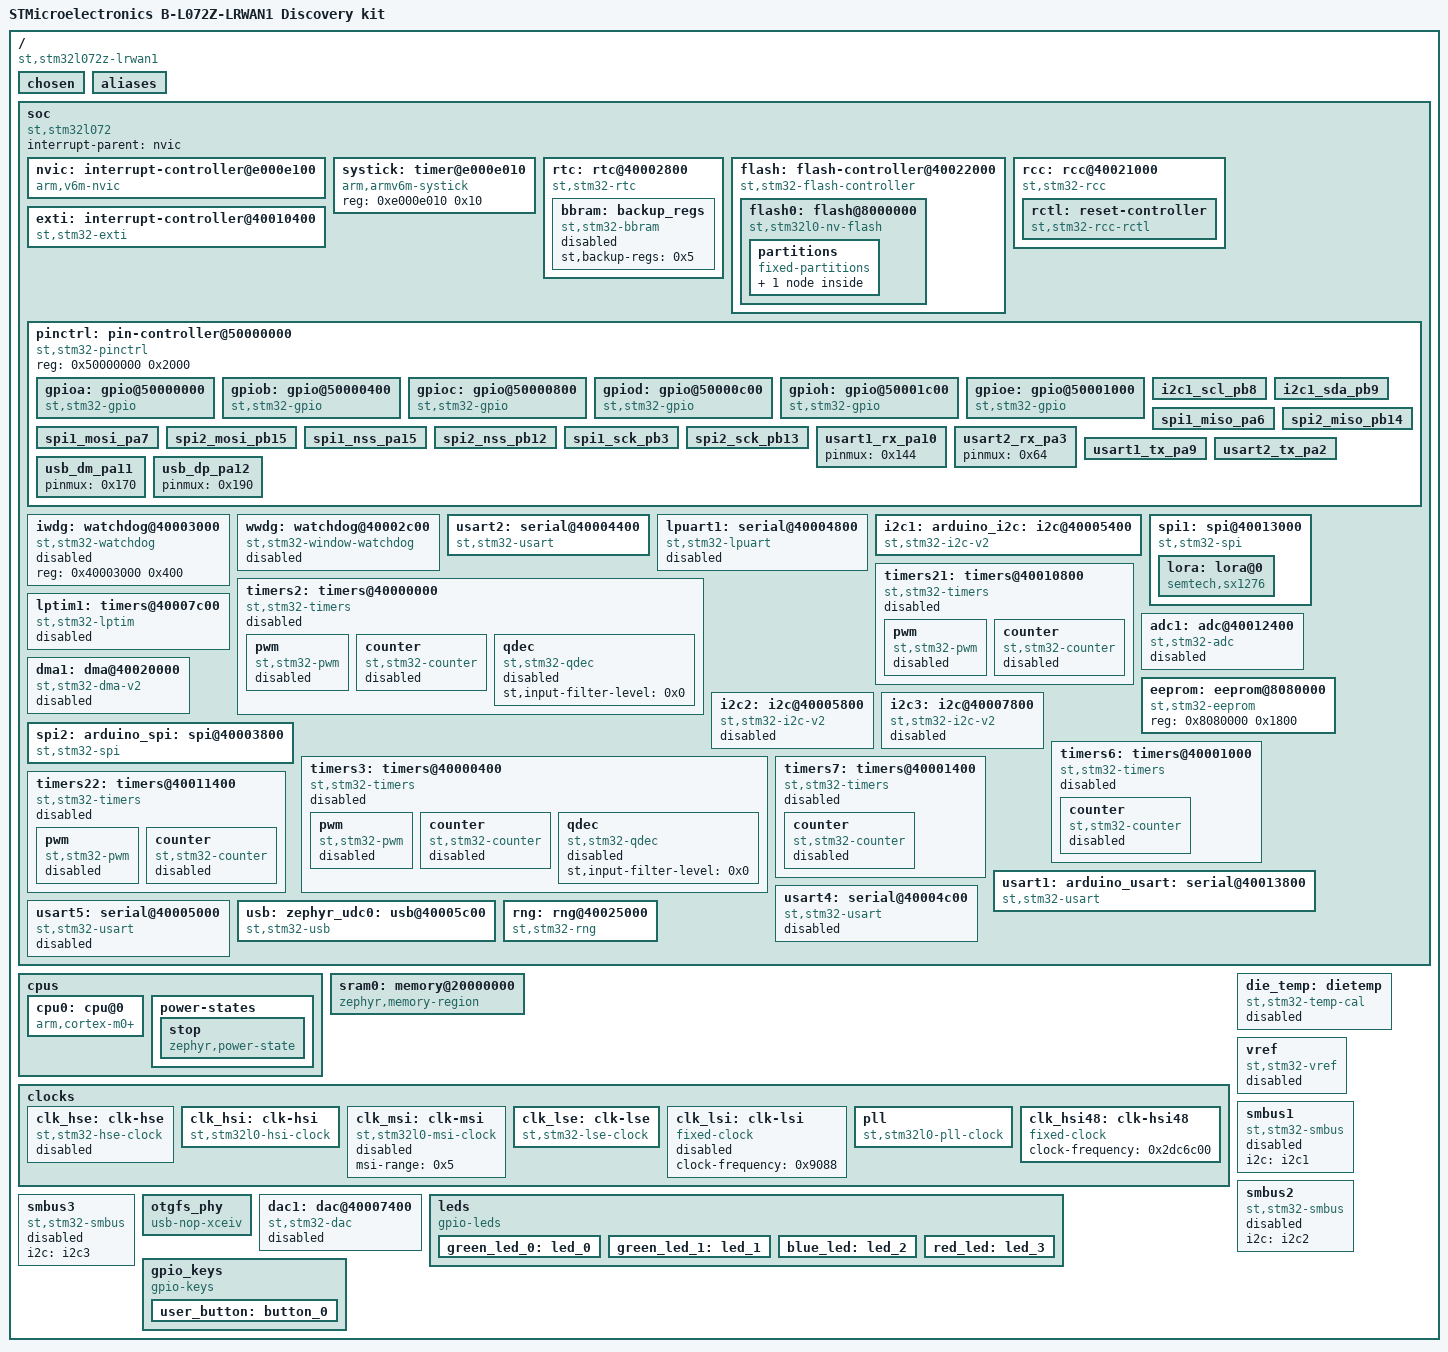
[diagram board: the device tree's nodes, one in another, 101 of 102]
/dts-v1/;

/* node '/' defined in zephyr/dts/common/skeleton.dtsi:9 */
/ {
	#address-cells = < 0x1 >;                                  /* in zephyr/dts/common/skeleton.dtsi:10 */
	#size-cells = < 0x1 >;                                     /* in zephyr/dts/common/skeleton.dtsi:11 */
	model = "STMicroelectronics B-L072Z-LRWAN1 Discovery kit"; /* in zephyr/boards/st/b_l072z_lrwan1/b_l072z_lrwan1.dts:13 */
	compatible = "st,stm32l072z-lrwan1";                       /* in zephyr/boards/st/b_l072z_lrwan1/b_l072z_lrwan1.dts:14 */

	/* node '/chosen' defined in zephyr/dts/common/skeleton.dtsi:13 */
	chosen {
		zephyr,flash-controller = &flash; /* in zephyr/dts/arm/st/l0/stm32l0.dtsi:24 */
		zephyr,entropy = &rng;            /* in zephyr/dts/arm/st/l0/stm32l072.dtsi:11 */
		zephyr,console = &usart2;         /* in zephyr/boards/st/b_l072z_lrwan1/b_l072z_lrwan1.dts:17 */
		zephyr,shell-uart = &usart2;      /* in zephyr/boards/st/b_l072z_lrwan1/b_l072z_lrwan1.dts:18 */
		zephyr,sram = &sram0;             /* in zephyr/boards/st/b_l072z_lrwan1/b_l072z_lrwan1.dts:19 */
		zephyr,flash = &flash0;           /* in zephyr/boards/st/b_l072z_lrwan1/b_l072z_lrwan1.dts:20 */
	};

	/* node '/aliases' defined in zephyr/dts/common/skeleton.dtsi:15 */
	aliases {
		led0 = &green_led_0; /* in zephyr/boards/st/b_l072z_lrwan1/b_l072z_lrwan1.dts:59 */
		led1 = &green_led_1; /* in zephyr/boards/st/b_l072z_lrwan1/b_l072z_lrwan1.dts:60 */
		led2 = &blue_led;    /* in zephyr/boards/st/b_l072z_lrwan1/b_l072z_lrwan1.dts:61 */
		led3 = &red_led;     /* in zephyr/boards/st/b_l072z_lrwan1/b_l072z_lrwan1.dts:62 */
		sw0 = &user_button;  /* in zephyr/boards/st/b_l072z_lrwan1/b_l072z_lrwan1.dts:63 */
		eeprom-0 = &eeprom;  /* in zephyr/boards/st/b_l072z_lrwan1/b_l072z_lrwan1.dts:64 */
		lora0 = &lora;       /* in zephyr/boards/st/b_l072z_lrwan1/b_l072z_lrwan1.dts:65 */
	};

	/* node '/soc' defined in zephyr/dts/arm/armv6-m.dtsi:6 */
	soc {
		#address-cells = < 0x1 >;     /* in zephyr/dts/arm/armv6-m.dtsi:7 */
		#size-cells = < 0x1 >;        /* in zephyr/dts/arm/armv6-m.dtsi:8 */
		interrupt-parent = < &nvic >; /* in zephyr/dts/arm/armv6-m.dtsi:10 */
		ranges;                       /* in zephyr/dts/arm/armv6-m.dtsi:11 */
		compatible = "st,stm32l072",
		             "st,stm32l0",
		             "simple-bus";    /* in zephyr/dts/arm/st/l0/stm32l072.dtsi:24 */

		/* node '/soc/interrupt-controller@e000e100' defined in zephyr/dts/arm/armv6-m.dtsi:13 */
		nvic: interrupt-controller@e000e100 {
			#address-cells = < 0x1 >;            /* in zephyr/dts/arm/armv6-m.dtsi:14 */
			compatible = "arm,v6m-nvic";         /* in zephyr/dts/arm/armv6-m.dtsi:15 */
			reg = < 0xe000e100 0xc00 >;          /* in zephyr/dts/arm/armv6-m.dtsi:16 */
			interrupt-controller;                /* in zephyr/dts/arm/armv6-m.dtsi:17 */
			#interrupt-cells = < 0x2 >;          /* in zephyr/dts/arm/armv6-m.dtsi:18 */
			arm,num-irq-priority-bits = < 0x2 >; /* in zephyr/dts/arm/st/l0/stm32l0.dtsi:384 */
			phandle = < 0x1 >;                   /* in zephyr/dts/arm/armv6-m.dtsi:10 */
		};

		/* node '/soc/timer@e000e010' defined in zephyr/dts/arm/armv6-m.dtsi:21 */
		systick: timer@e000e010 {
			compatible = "arm,armv6m-systick"; /* in zephyr/dts/arm/armv6-m.dtsi:22 */
			reg = < 0xe000e010 0x10 >;         /* in zephyr/dts/arm/armv6-m.dtsi:23 */
		};

		/* node '/soc/rtc@40002800' defined in zephyr/dts/arm/st/l0/stm32l0.dtsi:98 */
		rtc: rtc@40002800 {
			compatible = "st,stm32-rtc";       /* in zephyr/dts/arm/st/l0/stm32l0.dtsi:99 */
			reg = < 0x40002800 0x400 >;        /* in zephyr/dts/arm/st/l0/stm32l0.dtsi:100 */
			interrupts = < 0x2 0x0 >;          /* in zephyr/dts/arm/st/l0/stm32l0.dtsi:101 */
			prescaler = < 0x8000 >;            /* in zephyr/dts/arm/st/l0/stm32l0.dtsi:103 */
			alarms-count = < 0x2 >;            /* in zephyr/dts/arm/st/l0/stm32l0.dtsi:104 */
			alrm-exti-line = < 0x11 >;         /* in zephyr/dts/arm/st/l0/stm32l0.dtsi:105 */
			clocks = < &rcc 0x38 0x10000000 >,
			         < &rcc 0x2 0x1300050 >;   /* in zephyr/boards/st/b_l072z_lrwan1/b_l072z_lrwan1.dts:157 */
			status = "okay";                   /* in zephyr/boards/st/b_l072z_lrwan1/b_l072z_lrwan1.dts:159 */

			/* node '/soc/rtc@40002800/backup_regs' defined in zephyr/dts/arm/st/l0/stm32l0.dtsi:108 */
			bbram: backup_regs {
				compatible = "st,stm32-bbram"; /* in zephyr/dts/arm/st/l0/stm32l0.dtsi:109 */
				st,backup-regs = < 0x5 >;      /* in zephyr/dts/arm/st/l0/stm32l0.dtsi:110 */
				status = "disabled";           /* in zephyr/dts/arm/st/l0/stm32l0.dtsi:111 */
			};
		};

		/* node '/soc/flash-controller@40022000' defined in zephyr/dts/arm/st/l0/stm32l0.dtsi:115 */
		flash: flash-controller@40022000 {
			compatible = "st,stm32-flash-controller",
			             "st,stm32f1-flash-controller"; /* in zephyr/dts/arm/st/l0/stm32l0.dtsi:116 */
			reg = < 0x40022000 0x400 >;                 /* in zephyr/dts/arm/st/l0/stm32l0.dtsi:117 */
			interrupts = < 0x3 0x0 >;                   /* in zephyr/dts/arm/st/l0/stm32l0.dtsi:118 */
			#address-cells = < 0x1 >;                   /* in zephyr/dts/arm/st/l0/stm32l0.dtsi:120 */
			#size-cells = < 0x1 >;                      /* in zephyr/dts/arm/st/l0/stm32l0.dtsi:121 */

			/* node '/soc/flash-controller@40022000/flash@8000000' defined in zephyr/dts/arm/st/l0/stm32l0.dtsi:123 */
			flash0: flash@8000000 {
				compatible = "st,stm32l0-nv-flash",
				             "st,stm32-nv-flash",
				             "soc-nv-flash";        /* in zephyr/dts/arm/st/l0/stm32l0.dtsi:124 */
				write-block-size = < 0x4 >;         /* in zephyr/dts/arm/st/l0/stm32l0.dtsi:127 */
				max-erase-time = < 0x4 >;           /* in zephyr/dts/arm/st/l0/stm32l0.dtsi:129 */
				reg = < 0x8000000 0x30000 >;        /* in zephyr/dts/arm/st/l0/stm32l072Xz.dtsi:17 */

				/* node '/soc/flash-controller@40022000/flash@8000000/partitions' defined in zephyr/boards/st/b_l072z_lrwan1/b_l072z_lrwan1.dts:177 */
				partitions {
					compatible = "fixed-partitions"; /* in zephyr/boards/st/b_l072z_lrwan1/b_l072z_lrwan1.dts:178 */
					#address-cells = < 0x1 >;        /* in zephyr/boards/st/b_l072z_lrwan1/b_l072z_lrwan1.dts:179 */
					#size-cells = < 0x1 >;           /* in zephyr/boards/st/b_l072z_lrwan1/b_l072z_lrwan1.dts:180 */

					/* node '/soc/flash-controller@40022000/flash@8000000/partitions/partition@28000' defined in zephyr/boards/st/b_l072z_lrwan1/b_l072z_lrwan1.dts:183 */
					storage_partition: partition@28000 {
						label = "storage";        /* in zephyr/boards/st/b_l072z_lrwan1/b_l072z_lrwan1.dts:184 */
						reg = < 0x28000 0x8000 >; /* in zephyr/boards/st/b_l072z_lrwan1/b_l072z_lrwan1.dts:185 */
					};
				};
			};
		};

		/* node '/soc/rcc@40021000' defined in zephyr/dts/arm/st/l0/stm32l0.dtsi:133 */
		rcc: rcc@40021000 {
			compatible = "st,stm32-rcc";     /* in zephyr/dts/arm/st/l0/stm32l0.dtsi:134 */
			#clock-cells = < 0x2 >;          /* in zephyr/dts/arm/st/l0/stm32l0.dtsi:135 */
			reg = < 0x40021000 0x400 >;      /* in zephyr/dts/arm/st/l0/stm32l0.dtsi:136 */
			clocks = < &pll >;               /* in zephyr/boards/st/b_l072z_lrwan1/b_l072z_lrwan1.dts:89 */
			clock-frequency = < 0x1e84800 >; /* in zephyr/boards/st/b_l072z_lrwan1/b_l072z_lrwan1.dts:90 */
			ahb-prescaler = < 0x1 >;         /* in zephyr/boards/st/b_l072z_lrwan1/b_l072z_lrwan1.dts:91 */
			apb1-prescaler = < 0x1 >;        /* in zephyr/boards/st/b_l072z_lrwan1/b_l072z_lrwan1.dts:92 */
			apb2-prescaler = < 0x1 >;        /* in zephyr/boards/st/b_l072z_lrwan1/b_l072z_lrwan1.dts:93 */
			phandle = < 0x2 >;               /* in zephyr/boards/st/b_l072z_lrwan1/b_l072z_lrwan1.dts:157 */

			/* node '/soc/rcc@40021000/reset-controller' defined in zephyr/dts/arm/st/l0/stm32l0.dtsi:138 */
			rctl: reset-controller {
				compatible = "st,stm32-rcc-rctl"; /* in zephyr/dts/arm/st/l0/stm32l0.dtsi:139 */
				#reset-cells = < 0x1 >;           /* in zephyr/dts/arm/st/l0/stm32l0.dtsi:140 */
				phandle = < 0x4 >;                /* in zephyr/dts/arm/st/l0/stm32l0.dtsi:222 */
			};
		};

		/* node '/soc/interrupt-controller@40010400' defined in zephyr/dts/arm/st/l0/stm32l0.dtsi:144 */
		exti: interrupt-controller@40010400 {
			compatible = "st,stm32-exti"; /* in zephyr/dts/arm/st/l0/stm32l0.dtsi:145 */
			interrupt-controller;         /* in zephyr/dts/arm/st/l0/stm32l0.dtsi:146 */
			#interrupt-cells = < 0x1 >;   /* in zephyr/dts/arm/st/l0/stm32l0.dtsi:147 */
			#address-cells = < 0x0 >;     /* in zephyr/dts/arm/st/l0/stm32l0.dtsi:148 */
			reg = < 0x40010400 0x400 >;   /* in zephyr/dts/arm/st/l0/stm32l0.dtsi:149 */
			clocks = < &rcc 0x34 0x1 >;   /* in zephyr/dts/arm/st/l0/stm32l0.dtsi:150 */
			num-lines = < 0x20 >;         /* in zephyr/dts/arm/st/l0/stm32l0.dtsi:151 */
			interrupts = < 0x5 0x0 >,
			             < 0x6 0x0 >,
			             < 0x7 0x0 >;     /* in zephyr/dts/arm/st/l0/stm32l0.dtsi:152 */
			interrupt-names = "line0-1",
			                  "line2-3",
			                  "line4-15"; /* in zephyr/dts/arm/st/l0/stm32l0.dtsi:153 */
			line-ranges = < 0x0 0x2 >,
			              < 0x2 0x2 >,
			              < 0x4 0xc >;    /* in zephyr/dts/arm/st/l0/stm32l0.dtsi:154 */
		};

		/* node '/soc/pin-controller@50000000' defined in zephyr/dts/arm/st/l0/stm32l0.dtsi:157 */
		pinctrl: pin-controller@50000000 {
			compatible = "st,stm32-pinctrl"; /* in zephyr/dts/arm/st/l0/stm32l0.dtsi:158 */
			#address-cells = < 0x1 >;        /* in zephyr/dts/arm/st/l0/stm32l0.dtsi:159 */
			#size-cells = < 0x1 >;           /* in zephyr/dts/arm/st/l0/stm32l0.dtsi:160 */
			reg = < 0x50000000 0x2000 >;     /* in zephyr/dts/arm/st/l0/stm32l0.dtsi:161 */

			/* node '/soc/pin-controller@50000000/gpio@50000000' defined in zephyr/dts/arm/st/l0/stm32l0.dtsi:163 */
			gpioa: gpio@50000000 {
				compatible = "st,stm32-gpio"; /* in zephyr/dts/arm/st/l0/stm32l0.dtsi:164 */
				gpio-controller;              /* in zephyr/dts/arm/st/l0/stm32l0.dtsi:165 */
				#gpio-cells = < 0x2 >;        /* in zephyr/dts/arm/st/l0/stm32l0.dtsi:166 */
				reg = < 0x50000000 0x400 >;   /* in zephyr/dts/arm/st/l0/stm32l0.dtsi:167 */
				clocks = < &rcc 0x2c 0x1 >;   /* in zephyr/dts/arm/st/l0/stm32l0.dtsi:168 */
				phandle = < 0xd >;            /* in zephyr/boards/st/b_l072z_lrwan1/b_l072z_lrwan1.dts:121 */
			};

			/* node '/soc/pin-controller@50000000/gpio@50000400' defined in zephyr/dts/arm/st/l0/stm32l0.dtsi:171 */
			gpiob: gpio@50000400 {
				compatible = "st,stm32-gpio"; /* in zephyr/dts/arm/st/l0/stm32l0.dtsi:172 */
				gpio-controller;              /* in zephyr/dts/arm/st/l0/stm32l0.dtsi:173 */
				#gpio-cells = < 0x2 >;        /* in zephyr/dts/arm/st/l0/stm32l0.dtsi:174 */
				reg = < 0x50000400 0x400 >;   /* in zephyr/dts/arm/st/l0/stm32l0.dtsi:175 */
				clocks = < &rcc 0x2c 0x2 >;   /* in zephyr/dts/arm/st/l0/stm32l0.dtsi:176 */
				phandle = < 0xf >;            /* in zephyr/boards/st/b_l072z_lrwan1/b_l072z_lrwan1.dts:127 */
			};

			/* node '/soc/pin-controller@50000000/gpio@50000800' defined in zephyr/dts/arm/st/l0/stm32l0.dtsi:179 */
			gpioc: gpio@50000800 {
				compatible = "st,stm32-gpio"; /* in zephyr/dts/arm/st/l0/stm32l0.dtsi:180 */
				gpio-controller;              /* in zephyr/dts/arm/st/l0/stm32l0.dtsi:181 */
				#gpio-cells = < 0x2 >;        /* in zephyr/dts/arm/st/l0/stm32l0.dtsi:182 */
				reg = < 0x50000800 0x400 >;   /* in zephyr/dts/arm/st/l0/stm32l0.dtsi:183 */
				clocks = < &rcc 0x2c 0x4 >;   /* in zephyr/dts/arm/st/l0/stm32l0.dtsi:184 */
				phandle = < 0xe >;            /* in zephyr/boards/st/b_l072z_lrwan1/b_l072z_lrwan1.dts:126 */
			};

			/* node '/soc/pin-controller@50000000/gpio@50000c00' defined in zephyr/dts/arm/st/l0/stm32l0.dtsi:187 */
			gpiod: gpio@50000c00 {
				compatible = "st,stm32-gpio"; /* in zephyr/dts/arm/st/l0/stm32l0.dtsi:188 */
				gpio-controller;              /* in zephyr/dts/arm/st/l0/stm32l0.dtsi:189 */
				#gpio-cells = < 0x2 >;        /* in zephyr/dts/arm/st/l0/stm32l0.dtsi:190 */
				reg = < 0x50000c00 0x400 >;   /* in zephyr/dts/arm/st/l0/stm32l0.dtsi:191 */
				clocks = < &rcc 0x2c 0x8 >;   /* in zephyr/dts/arm/st/l0/stm32l0.dtsi:192 */
			};

			/* node '/soc/pin-controller@50000000/gpio@50001c00' defined in zephyr/dts/arm/st/l0/stm32l0.dtsi:195 */
			gpioh: gpio@50001c00 {
				compatible = "st,stm32-gpio"; /* in zephyr/dts/arm/st/l0/stm32l0.dtsi:196 */
				gpio-controller;              /* in zephyr/dts/arm/st/l0/stm32l0.dtsi:197 */
				#gpio-cells = < 0x2 >;        /* in zephyr/dts/arm/st/l0/stm32l0.dtsi:198 */
				reg = < 0x50001c00 0x400 >;   /* in zephyr/dts/arm/st/l0/stm32l0.dtsi:199 */
				clocks = < &rcc 0x2c 0x80 >;  /* in zephyr/dts/arm/st/l0/stm32l0.dtsi:200 */
			};

			/* node '/soc/pin-controller@50000000/gpio@50001000' defined in zephyr/dts/arm/st/l0/stm32l071.dtsi:14 */
			gpioe: gpio@50001000 {
				compatible = "st,stm32-gpio"; /* in zephyr/dts/arm/st/l0/stm32l071.dtsi:15 */
				gpio-controller;              /* in zephyr/dts/arm/st/l0/stm32l071.dtsi:16 */
				#gpio-cells = < 0x2 >;        /* in zephyr/dts/arm/st/l0/stm32l071.dtsi:17 */
				reg = < 0x50001000 0x400 >;   /* in zephyr/dts/arm/st/l0/stm32l071.dtsi:18 */
				clocks = < &rcc 0x2c 0x10 >;  /* in zephyr/dts/arm/st/l0/stm32l071.dtsi:19 */
			};

			/* node '/soc/pin-controller@50000000/i2c1_scl_pb8' defined in modules/hal/stm32/dts/st/l0/stm32l072c(b-z)tx-pinctrl.dtsi:309 */
			i2c1_scl_pb8: i2c1_scl_pb8 {
				pinmux = < 0x304 >; /* in modules/hal/stm32/dts/st/l0/stm32l072c(b-z)tx-pinctrl.dtsi:310 */
				bias-pull-up;       /* in modules/hal/stm32/dts/st/l0/stm32l072c(b-z)tx-pinctrl.dtsi:311 */
				drive-open-drain;   /* in modules/hal/stm32/dts/st/l0/stm32l072c(b-z)tx-pinctrl.dtsi:312 */
				phandle = < 0x7 >;  /* in zephyr/boards/st/b_l072z_lrwan1/b_l072z_lrwan1.dts:150 */
			};

			/* node '/soc/pin-controller@50000000/i2c1_sda_pb9' defined in modules/hal/stm32/dts/st/l0/stm32l072c(b-z)tx-pinctrl.dtsi:347 */
			i2c1_sda_pb9: i2c1_sda_pb9 {
				pinmux = < 0x324 >; /* in modules/hal/stm32/dts/st/l0/stm32l072c(b-z)tx-pinctrl.dtsi:348 */
				bias-pull-up;       /* in modules/hal/stm32/dts/st/l0/stm32l072c(b-z)tx-pinctrl.dtsi:349 */
				drive-open-drain;   /* in modules/hal/stm32/dts/st/l0/stm32l072c(b-z)tx-pinctrl.dtsi:350 */
				phandle = < 0x8 >;  /* in zephyr/boards/st/b_l072z_lrwan1/b_l072z_lrwan1.dts:150 */
			};

			/* node '/soc/pin-controller@50000000/spi1_miso_pa6' defined in modules/hal/stm32/dts/st/l0/stm32l072c(b-z)tx-pinctrl.dtsi:447 */
			spi1_miso_pa6: spi1_miso_pa6 {
				pinmux = < 0xc0 >; /* in modules/hal/stm32/dts/st/l0/stm32l072c(b-z)tx-pinctrl.dtsi:448 */
				bias-pull-down;    /* in modules/hal/stm32/dts/st/l0/stm32l072c(b-z)tx-pinctrl.dtsi:449 */
				phandle = < 0xb >; /* in zephyr/boards/st/b_l072z_lrwan1/b_l072z_lrwan1.dts:117 */
			};

			/* node '/soc/pin-controller@50000000/spi2_miso_pb14' defined in modules/hal/stm32/dts/st/l0/stm32l072c(b-z)tx-pinctrl.dtsi:462 */
			spi2_miso_pb14: spi2_miso_pb14 {
				pinmux = < 0x3c0 >; /* in modules/hal/stm32/dts/st/l0/stm32l072c(b-z)tx-pinctrl.dtsi:463 */
				bias-pull-down;     /* in modules/hal/stm32/dts/st/l0/stm32l072c(b-z)tx-pinctrl.dtsi:464 */
				phandle = < 0x12 >; /* in zephyr/boards/st/b_l072z_lrwan1/b_l072z_lrwan1.dts:143 */
			};

			/* node '/soc/pin-controller@50000000/spi1_mosi_pa7' defined in modules/hal/stm32/dts/st/l0/stm32l072c(b-z)tx-pinctrl.dtsi:469 */
			spi1_mosi_pa7: spi1_mosi_pa7 {
				pinmux = < 0xe0 >; /* in modules/hal/stm32/dts/st/l0/stm32l072c(b-z)tx-pinctrl.dtsi:470 */
				bias-pull-down;    /* in modules/hal/stm32/dts/st/l0/stm32l072c(b-z)tx-pinctrl.dtsi:471 */
				phandle = < 0xc >; /* in zephyr/boards/st/b_l072z_lrwan1/b_l072z_lrwan1.dts:117 */
			};

			/* node '/soc/pin-controller@50000000/spi2_mosi_pb15' defined in modules/hal/stm32/dts/st/l0/stm32l072c(b-z)tx-pinctrl.dtsi:484 */
			spi2_mosi_pb15: spi2_mosi_pb15 {
				pinmux = < 0x3e0 >; /* in modules/hal/stm32/dts/st/l0/stm32l072c(b-z)tx-pinctrl.dtsi:485 */
				bias-pull-down;     /* in modules/hal/stm32/dts/st/l0/stm32l072c(b-z)tx-pinctrl.dtsi:486 */
				phandle = < 0x13 >; /* in zephyr/boards/st/b_l072z_lrwan1/b_l072z_lrwan1.dts:143 */
			};

			/* node '/soc/pin-controller@50000000/spi1_nss_pa15' defined in modules/hal/stm32/dts/st/l0/stm32l072c(b-z)tx-pinctrl.dtsi:496 */
			spi1_nss_pa15: spi1_nss_pa15 {
				pinmux = < 0x1e0 >; /* in modules/hal/stm32/dts/st/l0/stm32l072c(b-z)tx-pinctrl.dtsi:497 */
				bias-pull-up;       /* in modules/hal/stm32/dts/st/l0/stm32l072c(b-z)tx-pinctrl.dtsi:498 */
				phandle = < 0x9 >;  /* in zephyr/boards/st/b_l072z_lrwan1/b_l072z_lrwan1.dts:117 */
			};

			/* node '/soc/pin-controller@50000000/spi2_nss_pb12' defined in modules/hal/stm32/dts/st/l0/stm32l072c(b-z)tx-pinctrl.dtsi:506 */
			spi2_nss_pb12: spi2_nss_pb12 {
				pinmux = < 0x380 >; /* in modules/hal/stm32/dts/st/l0/stm32l072c(b-z)tx-pinctrl.dtsi:507 */
				bias-pull-up;       /* in modules/hal/stm32/dts/st/l0/stm32l072c(b-z)tx-pinctrl.dtsi:508 */
				phandle = < 0x10 >; /* in zephyr/boards/st/b_l072z_lrwan1/b_l072z_lrwan1.dts:143 */
			};

			/* node '/soc/pin-controller@50000000/spi1_sck_pb3' defined in modules/hal/stm32/dts/st/l0/stm32l072c(b-z)tx-pinctrl.dtsi:519 */
			spi1_sck_pb3: spi1_sck_pb3 {
				pinmux = < 0x260 >;            /* in modules/hal/stm32/dts/st/l0/stm32l072c(b-z)tx-pinctrl.dtsi:520 */
				bias-pull-down;                /* in modules/hal/stm32/dts/st/l0/stm32l072c(b-z)tx-pinctrl.dtsi:521 */
				slew-rate = "very-high-speed"; /* in modules/hal/stm32/dts/st/l0/stm32l072c(b-z)tx-pinctrl.dtsi:522 */
				phandle = < 0xa >;             /* in zephyr/boards/st/b_l072z_lrwan1/b_l072z_lrwan1.dts:117 */
			};

			/* node '/soc/pin-controller@50000000/spi2_sck_pb13' defined in modules/hal/stm32/dts/st/l0/stm32l072c(b-z)tx-pinctrl.dtsi:531 */
			spi2_sck_pb13: spi2_sck_pb13 {
				pinmux = < 0x3a0 >;            /* in modules/hal/stm32/dts/st/l0/stm32l072c(b-z)tx-pinctrl.dtsi:532 */
				bias-pull-down;                /* in modules/hal/stm32/dts/st/l0/stm32l072c(b-z)tx-pinctrl.dtsi:533 */
				slew-rate = "very-high-speed"; /* in modules/hal/stm32/dts/st/l0/stm32l072c(b-z)tx-pinctrl.dtsi:534 */
				phandle = < 0x11 >;            /* in zephyr/boards/st/b_l072z_lrwan1/b_l072z_lrwan1.dts:143 */
			};

			/* node '/soc/pin-controller@50000000/usart1_rx_pa10' defined in modules/hal/stm32/dts/st/l0/stm32l072c(b-z)tx-pinctrl.dtsi:855 */
			usart1_rx_pa10: usart1_rx_pa10 {
				pinmux = < 0x144 >; /* in modules/hal/stm32/dts/st/l0/stm32l072c(b-z)tx-pinctrl.dtsi:856 */
				phandle = < 0x15 >; /* in zephyr/boards/st/b_l072z_lrwan1/b_l072z_lrwan1.dts:103 */
			};

			/* node '/soc/pin-controller@50000000/usart2_rx_pa3' defined in modules/hal/stm32/dts/st/l0/stm32l072c(b-z)tx-pinctrl.dtsi:875 */
			usart2_rx_pa3: usart2_rx_pa3 {
				pinmux = < 0x64 >; /* in modules/hal/stm32/dts/st/l0/stm32l072c(b-z)tx-pinctrl.dtsi:876 */
				phandle = < 0x6 >; /* in zephyr/boards/st/b_l072z_lrwan1/b_l072z_lrwan1.dts:110 */
			};

			/* node '/soc/pin-controller@50000000/usart1_tx_pa9' defined in modules/hal/stm32/dts/st/l0/stm32l072c(b-z)tx-pinctrl.dtsi:898 */
			usart1_tx_pa9: usart1_tx_pa9 {
				pinmux = < 0x124 >; /* in modules/hal/stm32/dts/st/l0/stm32l072c(b-z)tx-pinctrl.dtsi:899 */
				bias-pull-up;       /* in modules/hal/stm32/dts/st/l0/stm32l072c(b-z)tx-pinctrl.dtsi:900 */
				phandle = < 0x14 >; /* in zephyr/boards/st/b_l072z_lrwan1/b_l072z_lrwan1.dts:103 */
			};

			/* node '/soc/pin-controller@50000000/usart2_tx_pa2' defined in modules/hal/stm32/dts/st/l0/stm32l072c(b-z)tx-pinctrl.dtsi:923 */
			usart2_tx_pa2: usart2_tx_pa2 {
				pinmux = < 0x44 >; /* in modules/hal/stm32/dts/st/l0/stm32l072c(b-z)tx-pinctrl.dtsi:924 */
				bias-pull-up;      /* in modules/hal/stm32/dts/st/l0/stm32l072c(b-z)tx-pinctrl.dtsi:925 */
				phandle = < 0x5 >; /* in zephyr/boards/st/b_l072z_lrwan1/b_l072z_lrwan1.dts:110 */
			};

			/* node '/soc/pin-controller@50000000/usb_dm_pa11' defined in modules/hal/stm32/dts/st/l0/stm32l072c(b-z)tx-pinctrl.dtsi:945 */
			usb_dm_pa11: usb_dm_pa11 {
				pinmux = < 0x170 >; /* in modules/hal/stm32/dts/st/l0/stm32l072c(b-z)tx-pinctrl.dtsi:946 */
				phandle = < 0x17 >; /* in zephyr/boards/st/b_l072z_lrwan1/b_l072z_lrwan1.dts:171 */
			};

			/* node '/soc/pin-controller@50000000/usb_dp_pa12' defined in modules/hal/stm32/dts/st/l0/stm32l072c(b-z)tx-pinctrl.dtsi:949 */
			usb_dp_pa12: usb_dp_pa12 {
				pinmux = < 0x190 >; /* in modules/hal/stm32/dts/st/l0/stm32l072c(b-z)tx-pinctrl.dtsi:950 */
				phandle = < 0x18 >; /* in zephyr/boards/st/b_l072z_lrwan1/b_l072z_lrwan1.dts:171 */
			};
		};

		/* node '/soc/watchdog@40003000' defined in zephyr/dts/arm/st/l0/stm32l0.dtsi:204 */
		iwdg: watchdog@40003000 {
			compatible = "st,stm32-watchdog"; /* in zephyr/dts/arm/st/l0/stm32l0.dtsi:205 */
			reg = < 0x40003000 0x400 >;       /* in zephyr/dts/arm/st/l0/stm32l0.dtsi:206 */
			status = "disabled";              /* in zephyr/dts/arm/st/l0/stm32l0.dtsi:207 */
		};

		/* node '/soc/watchdog@40002c00' defined in zephyr/dts/arm/st/l0/stm32l0.dtsi:210 */
		wwdg: watchdog@40002c00 {
			compatible = "st,stm32-window-watchdog"; /* in zephyr/dts/arm/st/l0/stm32l0.dtsi:211 */
			reg = < 0x40002c00 0x400 >;              /* in zephyr/dts/arm/st/l0/stm32l0.dtsi:212 */
			clocks = < &rcc 0x38 0x800 >;            /* in zephyr/dts/arm/st/l0/stm32l0.dtsi:213 */
			interrupts = < 0x0 0x2 >;                /* in zephyr/dts/arm/st/l0/stm32l0.dtsi:214 */
			status = "disabled";                     /* in zephyr/dts/arm/st/l0/stm32l0.dtsi:215 */
		};

		/* node '/soc/serial@40004400' defined in zephyr/dts/arm/st/l0/stm32l0.dtsi:218 */
		usart2: serial@40004400 {
			compatible = "st,stm32-usart",
			             "st,stm32-uart";                  /* in zephyr/dts/arm/st/l0/stm32l0.dtsi:219 */
			reg = < 0x40004400 0x400 >;                    /* in zephyr/dts/arm/st/l0/stm32l0.dtsi:220 */
			clocks = < &rcc 0x38 0x20000 >;                /* in zephyr/dts/arm/st/l0/stm32l0.dtsi:221 */
			resets = < &rctl 0x511 >;                      /* in zephyr/dts/arm/st/l0/stm32l0.dtsi:222 */
			interrupts = < 0x1c 0x0 >;                     /* in zephyr/dts/arm/st/l0/stm32l0.dtsi:223 */
			pinctrl-0 = < &usart2_tx_pa2 &usart2_rx_pa3 >; /* in zephyr/boards/st/b_l072z_lrwan1/b_l072z_lrwan1.dts:110 */
			pinctrl-names = "default";                     /* in zephyr/boards/st/b_l072z_lrwan1/b_l072z_lrwan1.dts:111 */
			current-speed = < 0x1c200 >;                   /* in zephyr/boards/st/b_l072z_lrwan1/b_l072z_lrwan1.dts:112 */
			status = "okay";                               /* in zephyr/boards/st/b_l072z_lrwan1/b_l072z_lrwan1.dts:113 */
		};

		/* node '/soc/serial@40004800' defined in zephyr/dts/arm/st/l0/stm32l0.dtsi:227 */
		lpuart1: serial@40004800 {
			compatible = "st,stm32-lpuart",
			             "st,stm32-uart";   /* in zephyr/dts/arm/st/l0/stm32l0.dtsi:228 */
			reg = < 0x40004800 0x400 >;     /* in zephyr/dts/arm/st/l0/stm32l0.dtsi:229 */
			clocks = < &rcc 0x38 0x40000 >; /* in zephyr/dts/arm/st/l0/stm32l0.dtsi:230 */
			resets = < &rctl 0x512 >;       /* in zephyr/dts/arm/st/l0/stm32l0.dtsi:231 */
			interrupts = < 0x1d 0x0 >;      /* in zephyr/dts/arm/st/l0/stm32l0.dtsi:232 */
			status = "disabled";            /* in zephyr/dts/arm/st/l0/stm32l0.dtsi:233 */
		};

		/* node '/soc/i2c@40005400' defined in zephyr/dts/arm/st/l0/stm32l0.dtsi:236 */
		i2c1: arduino_i2c: i2c@40005400 {
			compatible = "st,stm32-i2c-v2";              /* in zephyr/dts/arm/st/l0/stm32l0.dtsi:237 */
			#address-cells = < 0x1 >;                    /* in zephyr/dts/arm/st/l0/stm32l0.dtsi:239 */
			#size-cells = < 0x0 >;                       /* in zephyr/dts/arm/st/l0/stm32l0.dtsi:240 */
			reg = < 0x40005400 0x400 >;                  /* in zephyr/dts/arm/st/l0/stm32l0.dtsi:241 */
			clocks = < &rcc 0x38 0x200000 >;             /* in zephyr/dts/arm/st/l0/stm32l0.dtsi:242 */
			interrupts = < 0x17 0x0 >;                   /* in zephyr/dts/arm/st/l0/stm32l0.dtsi:243 */
			interrupt-names = "combined";                /* in zephyr/dts/arm/st/l0/stm32l0.dtsi:244 */
			pinctrl-0 = < &i2c1_scl_pb8 &i2c1_sda_pb9 >; /* in zephyr/boards/st/b_l072z_lrwan1/b_l072z_lrwan1.dts:150 */
			pinctrl-names = "default";                   /* in zephyr/boards/st/b_l072z_lrwan1/b_l072z_lrwan1.dts:151 */
			status = "okay";                             /* in zephyr/boards/st/b_l072z_lrwan1/b_l072z_lrwan1.dts:152 */
			clock-frequency = < 0x61a80 >;               /* in zephyr/boards/st/b_l072z_lrwan1/b_l072z_lrwan1.dts:153 */
			phandle = < 0x1c >;                          /* in zephyr/dts/arm/st/l0/stm32l0.dtsi:378 */
		};

		/* node '/soc/spi@40013000' defined in zephyr/dts/arm/st/l0/stm32l0.dtsi:248 */
		spi1: spi@40013000 {
			compatible = "st,stm32-spi";                                                /* in zephyr/dts/arm/st/l0/stm32l0.dtsi:249 */
			#address-cells = < 0x1 >;                                                   /* in zephyr/dts/arm/st/l0/stm32l0.dtsi:250 */
			#size-cells = < 0x0 >;                                                      /* in zephyr/dts/arm/st/l0/stm32l0.dtsi:251 */
			reg = < 0x40013000 0x400 >;                                                 /* in zephyr/dts/arm/st/l0/stm32l0.dtsi:252 */
			clocks = < &rcc 0x34 0x1000 >;                                              /* in zephyr/dts/arm/st/l0/stm32l0.dtsi:253 */
			interrupts = < 0x19 0x3 >;                                                  /* in zephyr/dts/arm/st/l0/stm32l0.dtsi:254 */
			pinctrl-0 = < &spi1_nss_pa15 &spi1_sck_pb3 &spi1_miso_pa6 &spi1_mosi_pa7 >; /* in zephyr/boards/st/b_l072z_lrwan1/b_l072z_lrwan1.dts:117 */
			pinctrl-names = "default";                                                  /* in zephyr/boards/st/b_l072z_lrwan1/b_l072z_lrwan1.dts:119 */
			status = "okay";                                                            /* in zephyr/boards/st/b_l072z_lrwan1/b_l072z_lrwan1.dts:120 */
			cs-gpios = < &gpioa 0xf 0x1 >;                                              /* in zephyr/boards/st/b_l072z_lrwan1/b_l072z_lrwan1.dts:121 */

			/* node '/soc/spi@40013000/lora@0' defined in zephyr/boards/st/b_l072z_lrwan1/b_l072z_lrwan1.dts:123 */
			lora: lora@0 {
				compatible = "semtech,sx1276";              /* in zephyr/boards/st/b_l072z_lrwan1/b_l072z_lrwan1.dts:124 */
				reg = < 0x0 >;                              /* in zephyr/boards/st/b_l072z_lrwan1/b_l072z_lrwan1.dts:125 */
				reset-gpios = < &gpioc 0x0 0x1 >;           /* in zephyr/boards/st/b_l072z_lrwan1/b_l072z_lrwan1.dts:126 */
				dio-gpios = < &gpiob 0x4 0x20 >,
				            < &gpiob 0x1 0x20 >,
				            < &gpiob 0x0 0x20 >,
				            < &gpioc 0xd 0x20 >,
				            < &gpioa 0x5 0x20 >,
				            < &gpioa 0x4 0x20 >;            /* in zephyr/boards/st/b_l072z_lrwan1/b_l072z_lrwan1.dts:127 */
				rfi-enable-gpios = < &gpioa 0x1 0x0 >;      /* in zephyr/boards/st/b_l072z_lrwan1/b_l072z_lrwan1.dts:133 */
				rfo-enable-gpios = < &gpioc 0x2 0x0 >;      /* in zephyr/boards/st/b_l072z_lrwan1/b_l072z_lrwan1.dts:134 */
				pa-boost-enable-gpios = < &gpioc 0x1 0x0 >; /* in zephyr/boards/st/b_l072z_lrwan1/b_l072z_lrwan1.dts:135 */
				tcxo-power-gpios = < &gpioa 0xc 0x0 >;      /* in zephyr/boards/st/b_l072z_lrwan1/b_l072z_lrwan1.dts:136 */
				tcxo-power-startup-delay-ms = < 0x5 >;      /* in zephyr/boards/st/b_l072z_lrwan1/b_l072z_lrwan1.dts:137 */
				spi-max-frequency = < 0xf4240 >;            /* in zephyr/boards/st/b_l072z_lrwan1/b_l072z_lrwan1.dts:138 */
			};
		};

		/* node '/soc/timers@40000000' defined in zephyr/dts/arm/st/l0/stm32l0.dtsi:258 */
		timers2: timers@40000000 {
			compatible = "st,stm32-timers"; /* in zephyr/dts/arm/st/l0/stm32l0.dtsi:259 */
			reg = < 0x40000000 0x400 >;     /* in zephyr/dts/arm/st/l0/stm32l0.dtsi:260 */
			clocks = < &rcc 0x38 0x1 >,
			         < &rcc 0x8 0xff >;     /* in zephyr/dts/arm/st/l0/stm32l0.dtsi:261 */
			resets = < &rctl 0x500 >;       /* in zephyr/dts/arm/st/l0/stm32l0.dtsi:263 */
			interrupts = < 0xf 0x0 >;       /* in zephyr/dts/arm/st/l0/stm32l0.dtsi:264 */
			interrupt-names = "global";     /* in zephyr/dts/arm/st/l0/stm32l0.dtsi:265 */
			st,prescaler = < 0x0 >;         /* in zephyr/dts/arm/st/l0/stm32l0.dtsi:266 */
			status = "disabled";            /* in zephyr/dts/arm/st/l0/stm32l0.dtsi:267 */

			/* node '/soc/timers@40000000/pwm' defined in zephyr/dts/arm/st/l0/stm32l0.dtsi:269 */
			pwm {
				compatible = "st,stm32-pwm"; /* in zephyr/dts/arm/st/l0/stm32l0.dtsi:270 */
				status = "disabled";         /* in zephyr/dts/arm/st/l0/stm32l0.dtsi:271 */
				#pwm-cells = < 0x3 >;        /* in zephyr/dts/arm/st/l0/stm32l0.dtsi:272 */
			};

			/* node '/soc/timers@40000000/counter' defined in zephyr/dts/arm/st/l0/stm32l0.dtsi:275 */
			counter {
				compatible = "st,stm32-counter"; /* in zephyr/dts/arm/st/l0/stm32l0.dtsi:276 */
				status = "disabled";             /* in zephyr/dts/arm/st/l0/stm32l0.dtsi:277 */
			};

			/* node '/soc/timers@40000000/qdec' defined in zephyr/dts/arm/st/l0/stm32l0.dtsi:280 */
			qdec {
				compatible = "st,stm32-qdec";    /* in zephyr/dts/arm/st/l0/stm32l0.dtsi:281 */
				st,input-filter-level = < 0x0 >; /* in zephyr/dts/arm/st/l0/stm32l0.dtsi:282 */
				status = "disabled";             /* in zephyr/dts/arm/st/l0/stm32l0.dtsi:283 */
			};
		};

		/* node '/soc/timers@40010800' defined in zephyr/dts/arm/st/l0/stm32l0.dtsi:287 */
		timers21: timers@40010800 {
			compatible = "st,stm32-timers"; /* in zephyr/dts/arm/st/l0/stm32l0.dtsi:288 */
			reg = < 0x40010800 0x400 >;     /* in zephyr/dts/arm/st/l0/stm32l0.dtsi:289 */
			clocks = < &rcc 0x34 0x4 >,
			         < &rcc 0x9 0xff >;     /* in zephyr/dts/arm/st/l0/stm32l0.dtsi:290 */
			resets = < &rctl 0x482 >;       /* in zephyr/dts/arm/st/l0/stm32l0.dtsi:292 */
			interrupts = < 0x14 0x0 >;      /* in zephyr/dts/arm/st/l0/stm32l0.dtsi:293 */
			interrupt-names = "global";     /* in zephyr/dts/arm/st/l0/stm32l0.dtsi:294 */
			st,prescaler = < 0x0 >;         /* in zephyr/dts/arm/st/l0/stm32l0.dtsi:295 */
			status = "disabled";            /* in zephyr/dts/arm/st/l0/stm32l0.dtsi:296 */

			/* node '/soc/timers@40010800/pwm' defined in zephyr/dts/arm/st/l0/stm32l0.dtsi:298 */
			pwm {
				compatible = "st,stm32-pwm"; /* in zephyr/dts/arm/st/l0/stm32l0.dtsi:299 */
				status = "disabled";         /* in zephyr/dts/arm/st/l0/stm32l0.dtsi:300 */
				#pwm-cells = < 0x3 >;        /* in zephyr/dts/arm/st/l0/stm32l0.dtsi:301 */
			};

			/* node '/soc/timers@40010800/counter' defined in zephyr/dts/arm/st/l0/stm32l0.dtsi:304 */
			counter {
				compatible = "st,stm32-counter"; /* in zephyr/dts/arm/st/l0/stm32l0.dtsi:305 */
				status = "disabled";             /* in zephyr/dts/arm/st/l0/stm32l0.dtsi:306 */
			};
		};

		/* node '/soc/timers@40007c00' defined in zephyr/dts/arm/st/l0/stm32l0.dtsi:310 */
		lptim1: timers@40007c00 {
			compatible = "st,stm32-lptim";     /* in zephyr/dts/arm/st/l0/stm32l0.dtsi:311 */
			clocks = < &rcc 0x38 0x80000000 >; /* in zephyr/dts/arm/st/l0/stm32l0.dtsi:312 */
			#address-cells = < 0x1 >;          /* in zephyr/dts/arm/st/l0/stm32l0.dtsi:313 */
			#size-cells = < 0x0 >;             /* in zephyr/dts/arm/st/l0/stm32l0.dtsi:314 */
			reg = < 0x40007c00 0x400 >;        /* in zephyr/dts/arm/st/l0/stm32l0.dtsi:315 */
			interrupts = < 0xd 0x1 >;          /* in zephyr/dts/arm/st/l0/stm32l0.dtsi:316 */
			interrupt-names = "wakeup";        /* in zephyr/dts/arm/st/l0/stm32l0.dtsi:317 */
			status = "disabled";               /* in zephyr/dts/arm/st/l0/stm32l0.dtsi:318 */
		};

		/* node '/soc/adc@40012400' defined in zephyr/dts/arm/st/l0/stm32l0.dtsi:321 */
		adc1: adc@40012400 {
			compatible = "st,stm32-adc";                              /* in zephyr/dts/arm/st/l0/stm32l0.dtsi:322 */
			reg = < 0x40012400 0x400 >;                               /* in zephyr/dts/arm/st/l0/stm32l0.dtsi:323 */
			clocks = < &rcc 0x34 0x200 >;                             /* in zephyr/dts/arm/st/l0/stm32l0.dtsi:324 */
			clock-names = "adcx";                                     /* in zephyr/dts/arm/st/l0/stm32l0.dtsi:325 */
			interrupts = < 0xc 0x0 >;                                 /* in zephyr/dts/arm/st/l0/stm32l0.dtsi:326 */
			#io-channel-cells = < 0x1 >;                              /* in zephyr/dts/arm/st/l0/stm32l0.dtsi:327 */
			resolutions = < 0x60630c 0x51630c 0x42630c 0x33630c >;    /* in zephyr/dts/arm/st/l0/stm32l0.dtsi:328 */
			sampling-times = < 0x2 0x4 0x8 0xd 0x14 0x28 0x50 0xa1 >; /* in zephyr/dts/arm/st/l0/stm32l0.dtsi:332 */
			num-sampling-time-common-channels = < 0x1 >;              /* in zephyr/dts/arm/st/l0/stm32l0.dtsi:333 */
			st,adc-sequencer = "fixed";                               /* in zephyr/dts/arm/st/l0/stm32l0.dtsi:334 */
			st,adc-oversampler = "minimal";                           /* in zephyr/dts/arm/st/l0/stm32l0.dtsi:335 */
			st,adc-internal-regulator = "startup-sw-delay";           /* in zephyr/dts/arm/st/l0/stm32l0.dtsi:336 */
			status = "disabled";                                      /* in zephyr/dts/arm/st/l0/stm32l0.dtsi:337 */
			phandle = < 0x1b >;                                       /* in zephyr/dts/arm/st/l0/stm32l0.dtsi:362 */
		};

		/* node '/soc/dma@40020000' defined in zephyr/dts/arm/st/l0/stm32l0.dtsi:340 */
		dma1: dma@40020000 {
			compatible = "st,stm32-dma-v2";                                           /* in zephyr/dts/arm/st/l0/stm32l0.dtsi:341 */
			#dma-cells = < 0x3 >;                                                     /* in zephyr/dts/arm/st/l0/stm32l0.dtsi:342 */
			reg = < 0x40020000 0x400 >;                                               /* in zephyr/dts/arm/st/l0/stm32l0.dtsi:343 */
			interrupts = < 0x9 0x0 0xa 0x0 0xa 0x0 0xb 0x0 0xb 0x0 0xb 0x0 0xb 0x0 >; /* in zephyr/dts/arm/st/l0/stm32l0.dtsi:344 */
			clocks = < &rcc 0x30 0x1 >;                                               /* in zephyr/dts/arm/st/l0/stm32l0.dtsi:345 */
			status = "disabled";                                                      /* in zephyr/dts/arm/st/l0/stm32l0.dtsi:346 */
		};

		/* node '/soc/eeprom@8080000' defined in zephyr/dts/arm/st/l0/stm32l0.dtsi:349 */
		eeprom: eeprom@8080000 {
			compatible = "st,stm32-eeprom"; /* in zephyr/dts/arm/st/l0/stm32l0.dtsi:350 */
			reg = < 0x8080000 0x1800 >;     /* in zephyr/dts/arm/st/l0/stm32l071.dtsi:171 */
			status = "okay";                /* in zephyr/boards/st/b_l072z_lrwan1/b_l072z_lrwan1.dts:167 */
		};

		/* node '/soc/i2c@40005800' defined in zephyr/dts/arm/st/l0/stm32l071.dtsi:23 */
		i2c2: i2c@40005800 {
			compatible = "st,stm32-i2c-v2";  /* in zephyr/dts/arm/st/l0/stm32l071.dtsi:24 */
			clock-frequency = < 0x186a0 >;   /* in zephyr/dts/arm/st/l0/stm32l071.dtsi:25 */
			#address-cells = < 0x1 >;        /* in zephyr/dts/arm/st/l0/stm32l071.dtsi:26 */
			#size-cells = < 0x0 >;           /* in zephyr/dts/arm/st/l0/stm32l071.dtsi:27 */
			reg = < 0x40005800 0x400 >;      /* in zephyr/dts/arm/st/l0/stm32l071.dtsi:28 */
			clocks = < &rcc 0x38 0x400000 >; /* in zephyr/dts/arm/st/l0/stm32l071.dtsi:29 */
			interrupts = < 0x18 0x0 >;       /* in zephyr/dts/arm/st/l0/stm32l071.dtsi:30 */
			interrupt-names = "combined";    /* in zephyr/dts/arm/st/l0/stm32l071.dtsi:31 */
			status = "disabled";             /* in zephyr/dts/arm/st/l0/stm32l071.dtsi:32 */
			phandle = < 0x1d >;              /* in zephyr/dts/arm/st/l0/stm32l071.dtsi:179 */
		};

		/* node '/soc/i2c@40007800' defined in zephyr/dts/arm/st/l0/stm32l071.dtsi:35 */
		i2c3: i2c@40007800 {
			compatible = "st,stm32-i2c-v2";    /* in zephyr/dts/arm/st/l0/stm32l071.dtsi:36 */
			clock-frequency = < 0x186a0 >;     /* in zephyr/dts/arm/st/l0/stm32l071.dtsi:37 */
			#address-cells = < 0x1 >;          /* in zephyr/dts/arm/st/l0/stm32l071.dtsi:38 */
			#size-cells = < 0x0 >;             /* in zephyr/dts/arm/st/l0/stm32l071.dtsi:39 */
			reg = < 0x40007800 0x400 >;        /* in zephyr/dts/arm/st/l0/stm32l071.dtsi:40 */
			clocks = < &rcc 0x38 0x40000000 >; /* in zephyr/dts/arm/st/l0/stm32l071.dtsi:41 */
			interrupts = < 0x15 0x0 >;         /* in zephyr/dts/arm/st/l0/stm32l071.dtsi:42 */
			interrupt-names = "combined";      /* in zephyr/dts/arm/st/l0/stm32l071.dtsi:43 */
			status = "disabled";               /* in zephyr/dts/arm/st/l0/stm32l071.dtsi:44 */
			phandle = < 0x1e >;                /* in zephyr/dts/arm/st/l0/stm32l071.dtsi:187 */
		};

		/* node '/soc/spi@40003800' defined in zephyr/dts/arm/st/l0/stm32l071.dtsi:47 */
		spi2: arduino_spi: spi@40003800 {
			compatible = "st,stm32-spi";                                                   /* in zephyr/dts/arm/st/l0/stm32l071.dtsi:48 */
			#address-cells = < 0x1 >;                                                      /* in zephyr/dts/arm/st/l0/stm32l071.dtsi:49 */
			#size-cells = < 0x0 >;                                                         /* in zephyr/dts/arm/st/l0/stm32l071.dtsi:50 */
			reg = < 0x40003800 0x400 >;                                                    /* in zephyr/dts/arm/st/l0/stm32l071.dtsi:51 */
			clocks = < &rcc 0x38 0x4000 >;                                                 /* in zephyr/dts/arm/st/l0/stm32l071.dtsi:52 */
			interrupts = < 0x1a 0x3 >;                                                     /* in zephyr/dts/arm/st/l0/stm32l071.dtsi:53 */
			pinctrl-0 = < &spi2_nss_pb12 &spi2_sck_pb13 &spi2_miso_pb14 &spi2_mosi_pb15 >; /* in zephyr/boards/st/b_l072z_lrwan1/b_l072z_lrwan1.dts:143 */
			pinctrl-names = "default";                                                     /* in zephyr/boards/st/b_l072z_lrwan1/b_l072z_lrwan1.dts:145 */
			status = "okay";                                                               /* in zephyr/boards/st/b_l072z_lrwan1/b_l072z_lrwan1.dts:146 */
		};

		/* node '/soc/timers@40000400' defined in zephyr/dts/arm/st/l0/stm32l071.dtsi:57 */
		timers3: timers@40000400 {
			compatible = "st,stm32-timers"; /* in zephyr/dts/arm/st/l0/stm32l071.dtsi:58 */
			reg = < 0x40000400 0x400 >;     /* in zephyr/dts/arm/st/l0/stm32l071.dtsi:59 */
			clocks = < &rcc 0x38 0x2 >,
			         < &rcc 0x8 0xff >;     /* in zephyr/dts/arm/st/l0/stm32l071.dtsi:60 */
			resets = < &rctl 0x501 >;       /* in zephyr/dts/arm/st/l0/stm32l071.dtsi:62 */
			interrupts = < 0x10 0x0 >;      /* in zephyr/dts/arm/st/l0/stm32l071.dtsi:63 */
			interrupt-names = "global";     /* in zephyr/dts/arm/st/l0/stm32l071.dtsi:64 */
			st,prescaler = < 0x0 >;         /* in zephyr/dts/arm/st/l0/stm32l071.dtsi:65 */
			status = "disabled";            /* in zephyr/dts/arm/st/l0/stm32l071.dtsi:66 */

			/* node '/soc/timers@40000400/pwm' defined in zephyr/dts/arm/st/l0/stm32l071.dtsi:68 */
			pwm {
				compatible = "st,stm32-pwm"; /* in zephyr/dts/arm/st/l0/stm32l071.dtsi:69 */
				status = "disabled";         /* in zephyr/dts/arm/st/l0/stm32l071.dtsi:70 */
				#pwm-cells = < 0x3 >;        /* in zephyr/dts/arm/st/l0/stm32l071.dtsi:71 */
			};

			/* node '/soc/timers@40000400/counter' defined in zephyr/dts/arm/st/l0/stm32l071.dtsi:74 */
			counter {
				compatible = "st,stm32-counter"; /* in zephyr/dts/arm/st/l0/stm32l071.dtsi:75 */
				status = "disabled";             /* in zephyr/dts/arm/st/l0/stm32l071.dtsi:76 */
			};

			/* node '/soc/timers@40000400/qdec' defined in zephyr/dts/arm/st/l0/stm32l071.dtsi:79 */
			qdec {
				compatible = "st,stm32-qdec";    /* in zephyr/dts/arm/st/l0/stm32l071.dtsi:80 */
				st,input-filter-level = < 0x0 >; /* in zephyr/dts/arm/st/l0/stm32l071.dtsi:81 */
				status = "disabled";             /* in zephyr/dts/arm/st/l0/stm32l071.dtsi:82 */
			};
		};

		/* node '/soc/timers@40001000' defined in zephyr/dts/arm/st/l0/stm32l071.dtsi:86 */
		timers6: timers@40001000 {
			compatible = "st,stm32-timers"; /* in zephyr/dts/arm/st/l0/stm32l071.dtsi:87 */
			reg = < 0x40001000 0x400 >;     /* in zephyr/dts/arm/st/l0/stm32l071.dtsi:88 */
			clocks = < &rcc 0x38 0x10 >,
			         < &rcc 0x8 0xff >;     /* in zephyr/dts/arm/st/l0/stm32l071.dtsi:89 */
			resets = < &rctl 0x504 >;       /* in zephyr/dts/arm/st/l0/stm32l071.dtsi:91 */
			interrupts = < 0x11 0x0 >;      /* in zephyr/dts/arm/st/l0/stm32l071.dtsi:92 */
			interrupt-names = "global";     /* in zephyr/dts/arm/st/l0/stm32l071.dtsi:93 */
			st,prescaler = < 0x0 >;         /* in zephyr/dts/arm/st/l0/stm32l071.dtsi:94 */
			status = "disabled";            /* in zephyr/dts/arm/st/l0/stm32l071.dtsi:95 */

			/* node '/soc/timers@40001000/counter' defined in zephyr/dts/arm/st/l0/stm32l071.dtsi:97 */
			counter {
				compatible = "st,stm32-counter"; /* in zephyr/dts/arm/st/l0/stm32l071.dtsi:98 */
				status = "disabled";             /* in zephyr/dts/arm/st/l0/stm32l071.dtsi:99 */
			};
		};

		/* node '/soc/timers@40001400' defined in zephyr/dts/arm/st/l0/stm32l071.dtsi:103 */
		timers7: timers@40001400 {
			compatible = "st,stm32-timers"; /* in zephyr/dts/arm/st/l0/stm32l071.dtsi:104 */
			reg = < 0x40001400 0x400 >;     /* in zephyr/dts/arm/st/l0/stm32l071.dtsi:105 */
			clocks = < &rcc 0x38 0x20 >,
			         < &rcc 0x8 0xff >;     /* in zephyr/dts/arm/st/l0/stm32l071.dtsi:106 */
			resets = < &rctl 0x505 >;       /* in zephyr/dts/arm/st/l0/stm32l071.dtsi:108 */
			interrupts = < 0x12 0x0 >;      /* in zephyr/dts/arm/st/l0/stm32l071.dtsi:109 */
			interrupt-names = "global";     /* in zephyr/dts/arm/st/l0/stm32l071.dtsi:110 */
			st,prescaler = < 0x0 >;         /* in zephyr/dts/arm/st/l0/stm32l071.dtsi:111 */
			status = "disabled";            /* in zephyr/dts/arm/st/l0/stm32l071.dtsi:112 */

			/* node '/soc/timers@40001400/counter' defined in zephyr/dts/arm/st/l0/stm32l071.dtsi:114 */
			counter {
				compatible = "st,stm32-counter"; /* in zephyr/dts/arm/st/l0/stm32l071.dtsi:115 */
				status = "disabled";             /* in zephyr/dts/arm/st/l0/stm32l071.dtsi:116 */
			};
		};

		/* node '/soc/timers@40011400' defined in zephyr/dts/arm/st/l0/stm32l071.dtsi:120 */
		timers22: timers@40011400 {
			compatible = "st,stm32-timers"; /* in zephyr/dts/arm/st/l0/stm32l071.dtsi:121 */
			reg = < 0x40011400 0x400 >;     /* in zephyr/dts/arm/st/l0/stm32l071.dtsi:122 */
			clocks = < &rcc 0x34 0x20 >,
			         < &rcc 0x9 0xff >;     /* in zephyr/dts/arm/st/l0/stm32l071.dtsi:123 */
			resets = < &rctl 0x485 >;       /* in zephyr/dts/arm/st/l0/stm32l071.dtsi:125 */
			interrupts = < 0x16 0x0 >;      /* in zephyr/dts/arm/st/l0/stm32l071.dtsi:126 */
			interrupt-names = "global";     /* in zephyr/dts/arm/st/l0/stm32l071.dtsi:127 */
			st,prescaler = < 0x0 >;         /* in zephyr/dts/arm/st/l0/stm32l071.dtsi:128 */
			status = "disabled";            /* in zephyr/dts/arm/st/l0/stm32l071.dtsi:129 */

			/* node '/soc/timers@40011400/pwm' defined in zephyr/dts/arm/st/l0/stm32l071.dtsi:131 */
			pwm {
				compatible = "st,stm32-pwm"; /* in zephyr/dts/arm/st/l0/stm32l071.dtsi:132 */
				status = "disabled";         /* in zephyr/dts/arm/st/l0/stm32l071.dtsi:133 */
				#pwm-cells = < 0x3 >;        /* in zephyr/dts/arm/st/l0/stm32l071.dtsi:134 */
			};

			/* node '/soc/timers@40011400/counter' defined in zephyr/dts/arm/st/l0/stm32l071.dtsi:137 */
			counter {
				compatible = "st,stm32-counter"; /* in zephyr/dts/arm/st/l0/stm32l071.dtsi:138 */
				status = "disabled";             /* in zephyr/dts/arm/st/l0/stm32l071.dtsi:139 */
			};
		};

		/* node '/soc/serial@40013800' defined in zephyr/dts/arm/st/l0/stm32l071.dtsi:143 */
		usart1: arduino_usart: serial@40013800 {
			compatible = "st,stm32-usart",
			             "st,stm32-uart";                   /* in zephyr/dts/arm/st/l0/stm32l071.dtsi:144 */
			reg = < 0x40013800 0x400 >;                     /* in zephyr/dts/arm/st/l0/stm32l071.dtsi:145 */
			clocks = < &rcc 0x34 0x4000 >;                  /* in zephyr/dts/arm/st/l0/stm32l071.dtsi:146 */
			resets = < &rctl 0x48e >;                       /* in zephyr/dts/arm/st/l0/stm32l071.dtsi:147 */
			interrupts = < 0x1b 0x0 >;                      /* in zephyr/dts/arm/st/l0/stm32l071.dtsi:148 */
			pinctrl-0 = < &usart1_tx_pa9 &usart1_rx_pa10 >; /* in zephyr/boards/st/b_l072z_lrwan1/b_l072z_lrwan1.dts:103 */
			pinctrl-names = "default";                      /* in zephyr/boards/st/b_l072z_lrwan1/b_l072z_lrwan1.dts:104 */
			current-speed = < 0x1c200 >;                    /* in zephyr/boards/st/b_l072z_lrwan1/b_l072z_lrwan1.dts:105 */
			status = "okay";                                /* in zephyr/boards/st/b_l072z_lrwan1/b_l072z_lrwan1.dts:106 */
		};

		/* node '/soc/serial@40004c00' defined in zephyr/dts/arm/st/l0/stm32l071.dtsi:152 */
		usart4: serial@40004c00 {
			compatible = "st,stm32-usart",
			             "st,stm32-uart";   /* in zephyr/dts/arm/st/l0/stm32l071.dtsi:153 */
			reg = < 0x40004c00 0x400 >;     /* in zephyr/dts/arm/st/l0/stm32l071.dtsi:154 */
			clocks = < &rcc 0x38 0x80000 >; /* in zephyr/dts/arm/st/l0/stm32l071.dtsi:155 */
			resets = < &rctl 0x513 >;       /* in zephyr/dts/arm/st/l0/stm32l071.dtsi:156 */
			interrupts = < 0xe 0x0 >;       /* in zephyr/dts/arm/st/l0/stm32l071.dtsi:157 */
			status = "disabled";            /* in zephyr/dts/arm/st/l0/stm32l071.dtsi:158 */
		};

		/* node '/soc/serial@40005000' defined in zephyr/dts/arm/st/l0/stm32l071.dtsi:161 */
		usart5: serial@40005000 {
			compatible = "st,stm32-usart",
			             "st,stm32-uart";    /* in zephyr/dts/arm/st/l0/stm32l071.dtsi:162 */
			reg = < 0x40005000 0x400 >;      /* in zephyr/dts/arm/st/l0/stm32l071.dtsi:163 */
			clocks = < &rcc 0x38 0x100000 >; /* in zephyr/dts/arm/st/l0/stm32l071.dtsi:164 */
			resets = < &rctl 0x514 >;        /* in zephyr/dts/arm/st/l0/stm32l071.dtsi:165 */
			interrupts = < 0xe 0x0 >;        /* in zephyr/dts/arm/st/l0/stm32l071.dtsi:166 */
			status = "disabled";             /* in zephyr/dts/arm/st/l0/stm32l071.dtsi:167 */
		};

		/* node '/soc/usb@40005c00' defined in zephyr/dts/arm/st/l0/stm32l072.dtsi:26 */
		usb: zephyr_udc0: usb@40005c00 {
			compatible = "st,stm32-usb";               /* in zephyr/dts/arm/st/l0/stm32l072.dtsi:27 */
			reg = < 0x40005c00 0x400 >;                /* in zephyr/dts/arm/st/l0/stm32l072.dtsi:28 */
			interrupts = < 0x1f 0x0 >;                 /* in zephyr/dts/arm/st/l0/stm32l072.dtsi:29 */
			interrupt-names = "usb";                   /* in zephyr/dts/arm/st/l0/stm32l072.dtsi:30 */
			num-bidir-endpoints = < 0x8 >;             /* in zephyr/dts/arm/st/l0/stm32l072.dtsi:31 */
			ram-size = < 0x400 >;                      /* in zephyr/dts/arm/st/l0/stm32l072.dtsi:32 */
			maximum-speed = "full-speed";              /* in zephyr/dts/arm/st/l0/stm32l072.dtsi:33 */
			phys = < &otgfs_phy >;                     /* in zephyr/dts/arm/st/l0/stm32l072.dtsi:34 */
			clocks = < &rcc 0x38 0x800000 >,
			         < &rcc 0x6 0x11a004c >;           /* in zephyr/dts/arm/st/l0/stm32l072.dtsi:35 */
			pinctrl-0 = < &usb_dm_pa11 &usb_dp_pa12 >; /* in zephyr/boards/st/b_l072z_lrwan1/b_l072z_lrwan1.dts:171 */
			pinctrl-names = "default";                 /* in zephyr/boards/st/b_l072z_lrwan1/b_l072z_lrwan1.dts:172 */
			status = "okay";                           /* in zephyr/boards/st/b_l072z_lrwan1/b_l072z_lrwan1.dts:173 */
		};

		/* node '/soc/rng@40025000' defined in zephyr/dts/arm/st/l0/stm32l072.dtsi:40 */
		rng: rng@40025000 {
			compatible = "st,stm32-rng";     /* in zephyr/dts/arm/st/l0/stm32l072.dtsi:41 */
			reg = < 0x40025000 0x400 >;      /* in zephyr/dts/arm/st/l0/stm32l072.dtsi:42 */
			interrupts = < 0x1d 0x0 >;       /* in zephyr/dts/arm/st/l0/stm32l072.dtsi:43 */
			clocks = < &rcc 0x30 0x100000 >; /* in zephyr/dts/arm/st/l0/stm32l072.dtsi:44 */
			status = "okay";                 /* in zephyr/boards/st/b_l072z_lrwan1/b_l072z_lrwan1.dts:163 */
		};
	};

	/* node '/cpus' defined in zephyr/dts/arm/st/l0/stm32l0.dtsi:27 */
	cpus {
		#address-cells = < 0x1 >; /* in zephyr/dts/arm/st/l0/stm32l0.dtsi:28 */
		#size-cells = < 0x0 >;    /* in zephyr/dts/arm/st/l0/stm32l0.dtsi:29 */

		/* node '/cpus/cpu@0' defined in zephyr/dts/arm/st/l0/stm32l0.dtsi:31 */
		cpu0: cpu@0 {
			device_type = "cpu";           /* in zephyr/dts/arm/st/l0/stm32l0.dtsi:32 */
			compatible = "arm,cortex-m0+"; /* in zephyr/dts/arm/st/l0/stm32l0.dtsi:33 */
			reg = < 0x0 >;                 /* in zephyr/dts/arm/st/l0/stm32l0.dtsi:34 */
			cpu-power-states = < &stop >;  /* in zephyr/dts/arm/st/l0/stm32l0.dtsi:35 */
		};

		/* node '/cpus/power-states' defined in zephyr/dts/arm/st/l0/stm32l0.dtsi:38 */
		power-states {

			/* node '/cpus/power-states/stop' defined in zephyr/dts/arm/st/l0/stm32l0.dtsi:39 */
			stop: stop {
				compatible = "zephyr,power-state";    /* in zephyr/dts/arm/st/l0/stm32l0.dtsi:40 */
				power-state-name = "suspend-to-idle"; /* in zephyr/dts/arm/st/l0/stm32l0.dtsi:41 */
				min-residency-us = < 0x7d0 >;         /* in zephyr/dts/arm/st/l0/stm32l0.dtsi:42 */
				exit-latency-us = < 0x2ee >;          /* in zephyr/dts/arm/st/l0/stm32l0.dtsi:43 */
				phandle = < 0x19 >;                   /* in zephyr/dts/arm/st/l0/stm32l0.dtsi:35 */
			};
		};
	};

	/* node '/memory@20000000' defined in zephyr/dts/arm/st/l0/stm32l0.dtsi:48 */
	sram0: memory@20000000 {
		compatible = "zephyr,memory-region",
		             "mmio-sram";            /* in zephyr/dts/arm/st/l0/stm32l0.dtsi:49 */
		zephyr,memory-region = "SRAM0";      /* in zephyr/dts/arm/st/l0/stm32l0.dtsi:50 */
		reg = < 0x20000000 0x5000 >;         /* in zephyr/dts/arm/st/l0/stm32l072Xz.dtsi:11 */
	};

	/* node '/clocks' defined in zephyr/dts/arm/st/l0/stm32l0.dtsi:53 */
	clocks {

		/* node '/clocks/clk-hse' defined in zephyr/dts/arm/st/l0/stm32l0.dtsi:54 */
		clk_hse: clk-hse {
			#clock-cells = < 0x0 >;            /* in zephyr/dts/arm/st/l0/stm32l0.dtsi:55 */
			compatible = "st,stm32-hse-clock"; /* in zephyr/dts/arm/st/l0/stm32l0.dtsi:56 */
			status = "disabled";               /* in zephyr/dts/arm/st/l0/stm32l0.dtsi:57 */
		};

		/* node '/clocks/clk-hsi' defined in zephyr/dts/arm/st/l0/stm32l0.dtsi:60 */
		clk_hsi: clk-hsi {
			#clock-cells = < 0x0 >;              /* in zephyr/dts/arm/st/l0/stm32l0.dtsi:61 */
			compatible = "st,stm32l0-hsi-clock"; /* in zephyr/dts/arm/st/l0/stm32l0.dtsi:62 */
			clock-frequency = < 0xf42400 >;      /* in zephyr/dts/arm/st/l0/stm32l0.dtsi:63 */
			hsi-div = < 0x1 >;                   /* in zephyr/dts/arm/st/l0/stm32l0.dtsi:64 */
			status = "okay";                     /* in zephyr/boards/st/b_l072z_lrwan1/b_l072z_lrwan1.dts:78 */
			phandle = < 0x1a >;                  /* in zephyr/boards/st/b_l072z_lrwan1/b_l072z_lrwan1.dts:84 */
		};

		/* node '/clocks/clk-msi' defined in zephyr/dts/arm/st/l0/stm32l0.dtsi:68 */
		clk_msi: clk-msi {
			#clock-cells = < 0x0 >;              /* in zephyr/dts/arm/st/l0/stm32l0.dtsi:69 */
			compatible = "st,stm32l0-msi-clock"; /* in zephyr/dts/arm/st/l0/stm32l0.dtsi:70 */
			msi-range = < 0x5 >;                 /* in zephyr/dts/arm/st/l0/stm32l0.dtsi:71 */
			status = "disabled";                 /* in zephyr/dts/arm/st/l0/stm32l0.dtsi:72 */
		};

		/* node '/clocks/clk-lse' defined in zephyr/dts/arm/st/l0/stm32l0.dtsi:75 */
		clk_lse: clk-lse {
			#clock-cells = < 0x0 >;            /* in zephyr/dts/arm/st/l0/stm32l0.dtsi:76 */
			compatible = "st,stm32-lse-clock"; /* in zephyr/dts/arm/st/l0/stm32l0.dtsi:77 */
			clock-frequency = < 0x8000 >;      /* in zephyr/dts/arm/st/l0/stm32l0.dtsi:78 */
			driving-capability = < 0x0 >;      /* in zephyr/dts/arm/st/l0/stm32l0.dtsi:79 */
			status = "okay";                   /* in zephyr/boards/st/b_l072z_lrwan1/b_l072z_lrwan1.dts:70 */
		};

		/* node '/clocks/clk-lsi' defined in zephyr/dts/arm/st/l0/stm32l0.dtsi:83 */
		clk_lsi: clk-lsi {
			#clock-cells = < 0x0 >;       /* in zephyr/dts/arm/st/l0/stm32l0.dtsi:84 */
			compatible = "fixed-clock";   /* in zephyr/dts/arm/st/l0/stm32l0.dtsi:85 */
			clock-frequency = < 0x9088 >; /* in zephyr/dts/arm/st/l0/stm32l0.dtsi:86 */
			status = "disabled";          /* in zephyr/dts/arm/st/l0/stm32l0.dtsi:87 */
		};

		/* node '/clocks/pll' defined in zephyr/dts/arm/st/l0/stm32l0.dtsi:90 */
		pll: pll {
			#clock-cells = < 0x0 >;              /* in zephyr/dts/arm/st/l0/stm32l0.dtsi:91 */
			compatible = "st,stm32l0-pll-clock"; /* in zephyr/dts/arm/st/l0/stm32l0.dtsi:92 */
			div = < 0x2 >;                       /* in zephyr/boards/st/b_l072z_lrwan1/b_l072z_lrwan1.dts:82 */
			mul = < 0x4 >;                       /* in zephyr/boards/st/b_l072z_lrwan1/b_l072z_lrwan1.dts:83 */
			clocks = < &clk_hsi >;               /* in zephyr/boards/st/b_l072z_lrwan1/b_l072z_lrwan1.dts:84 */
			status = "okay";                     /* in zephyr/boards/st/b_l072z_lrwan1/b_l072z_lrwan1.dts:85 */
			phandle = < 0x3 >;                   /* in zephyr/boards/st/b_l072z_lrwan1/b_l072z_lrwan1.dts:89 */
		};

		/* node '/clocks/clk-hsi48' defined in zephyr/dts/arm/st/l0/stm32l072.dtsi:15 */
		clk_hsi48: clk-hsi48 {
			#clock-cells = < 0x0 >;          /* in zephyr/dts/arm/st/l0/stm32l072.dtsi:16 */
			compatible = "fixed-clock";      /* in zephyr/dts/arm/st/l0/stm32l072.dtsi:17 */
			clock-frequency = < 0x2dc6c00 >; /* in zephyr/dts/arm/st/l0/stm32l072.dtsi:18 */
			status = "okay";                 /* in zephyr/boards/st/b_l072z_lrwan1/b_l072z_lrwan1.dts:74 */
		};
	};

	/* node '/dietemp' defined in zephyr/dts/arm/st/l0/stm32l0.dtsi:355 */
	die_temp: dietemp {
		compatible = "st,stm32-temp-cal"; /* in zephyr/dts/arm/st/l0/stm32l0.dtsi:356 */
		ts-cal1-addr = < 0x1ff8007a >;    /* in zephyr/dts/arm/st/l0/stm32l0.dtsi:357 */
		ts-cal2-addr = < 0x1ff8007e >;    /* in zephyr/dts/arm/st/l0/stm32l0.dtsi:358 */
		ts-cal1-temp = < 0x1e >;          /* in zephyr/dts/arm/st/l0/stm32l0.dtsi:359 */
		ts-cal2-temp = < 0x82 >;          /* in zephyr/dts/arm/st/l0/stm32l0.dtsi:360 */
		ts-cal-vrefanalog = < 0xbb8 >;    /* in zephyr/dts/arm/st/l0/stm32l0.dtsi:361 */
		io-channels = < &adc1 0x12 >;     /* in zephyr/dts/arm/st/l0/stm32l0.dtsi:362 */
		status = "disabled";              /* in zephyr/dts/arm/st/l0/stm32l0.dtsi:363 */
	};

	/* node '/vref' defined in zephyr/dts/arm/st/l0/stm32l0.dtsi:366 */
	vref: vref {
		compatible = "st,stm32-vref";      /* in zephyr/dts/arm/st/l0/stm32l0.dtsi:367 */
		vrefint-cal-addr = < 0x1ff80078 >; /* in zephyr/dts/arm/st/l0/stm32l0.dtsi:368 */
		vrefint-cal-mv = < 0xbb8 >;        /* in zephyr/dts/arm/st/l0/stm32l0.dtsi:369 */
		io-channels = < &adc1 0x11 >;      /* in zephyr/dts/arm/st/l0/stm32l0.dtsi:370 */
		status = "disabled";               /* in zephyr/dts/arm/st/l0/stm32l0.dtsi:371 */
	};

	/* node '/smbus1' defined in zephyr/dts/arm/st/l0/stm32l0.dtsi:374 */
	smbus1: smbus1 {
		compatible = "st,stm32-smbus"; /* in zephyr/dts/arm/st/l0/stm32l0.dtsi:375 */
		#address-cells = < 0x1 >;      /* in zephyr/dts/arm/st/l0/stm32l0.dtsi:376 */
		#size-cells = < 0x0 >;         /* in zephyr/dts/arm/st/l0/stm32l0.dtsi:377 */
		i2c = < &i2c1 >;               /* in zephyr/dts/arm/st/l0/stm32l0.dtsi:378 */
		status = "disabled";           /* in zephyr/dts/arm/st/l0/stm32l0.dtsi:379 */
	};

	/* node '/smbus2' defined in zephyr/dts/arm/st/l0/stm32l071.dtsi:175 */
	smbus2: smbus2 {
		compatible = "st,stm32-smbus"; /* in zephyr/dts/arm/st/l0/stm32l071.dtsi:176 */
		#address-cells = < 0x1 >;      /* in zephyr/dts/arm/st/l0/stm32l071.dtsi:177 */
		#size-cells = < 0x0 >;         /* in zephyr/dts/arm/st/l0/stm32l071.dtsi:178 */
		i2c = < &i2c2 >;               /* in zephyr/dts/arm/st/l0/stm32l071.dtsi:179 */
		status = "disabled";           /* in zephyr/dts/arm/st/l0/stm32l071.dtsi:180 */
	};

	/* node '/smbus3' defined in zephyr/dts/arm/st/l0/stm32l071.dtsi:183 */
	smbus3: smbus3 {
		compatible = "st,stm32-smbus"; /* in zephyr/dts/arm/st/l0/stm32l071.dtsi:184 */
		#address-cells = < 0x1 >;      /* in zephyr/dts/arm/st/l0/stm32l071.dtsi:185 */
		#size-cells = < 0x0 >;         /* in zephyr/dts/arm/st/l0/stm32l071.dtsi:186 */
		i2c = < &i2c3 >;               /* in zephyr/dts/arm/st/l0/stm32l071.dtsi:187 */
		status = "disabled";           /* in zephyr/dts/arm/st/l0/stm32l071.dtsi:188 */
	};

	/* node '/otgfs_phy' defined in zephyr/dts/arm/st/l0/stm32l072.dtsi:49 */
	otgfs_phy: otgfs_phy {
		compatible = "usb-nop-xceiv"; /* in zephyr/dts/arm/st/l0/stm32l072.dtsi:50 */
		#phy-cells = < 0x0 >;         /* in zephyr/dts/arm/st/l0/stm32l072.dtsi:51 */
		phandle = < 0x16 >;           /* in zephyr/dts/arm/st/l0/stm32l072.dtsi:34 */
	};

	/* node '/dac@40007400' defined in zephyr/dts/arm/st/l0/stm32l072.dtsi:54 */
	dac1: dac@40007400 {
		compatible = "st,stm32-dac";       /* in zephyr/dts/arm/st/l0/stm32l072.dtsi:55 */
		reg = < 0x40007400 0x400 >;        /* in zephyr/dts/arm/st/l0/stm32l072.dtsi:56 */
		clocks = < &rcc 0x38 0x20000000 >; /* in zephyr/dts/arm/st/l0/stm32l072.dtsi:57 */
		status = "disabled";               /* in zephyr/dts/arm/st/l0/stm32l072.dtsi:58 */
		#io-channel-cells = < 0x1 >;       /* in zephyr/dts/arm/st/l0/stm32l072.dtsi:59 */
	};

	/* node '/leds' defined in zephyr/boards/st/b_l072z_lrwan1/b_l072z_lrwan1.dts:23 */
	leds {
		compatible = "gpio-leds"; /* in zephyr/boards/st/b_l072z_lrwan1/b_l072z_lrwan1.dts:24 */

		/* node '/leds/led_0' defined in zephyr/boards/st/b_l072z_lrwan1/b_l072z_lrwan1.dts:26 */
		green_led_0: led_0 {
			gpios = < &gpioa 0x5 0x0 >; /* in zephyr/boards/st/b_l072z_lrwan1/b_l072z_lrwan1.dts:27 */
			label = "Green LED 1";      /* in zephyr/boards/st/b_l072z_lrwan1/b_l072z_lrwan1.dts:28 */
		};

		/* node '/leds/led_1' defined in zephyr/boards/st/b_l072z_lrwan1/b_l072z_lrwan1.dts:31 */
		green_led_1: led_1 {
			gpios = < &gpiob 0x5 0x0 >; /* in zephyr/boards/st/b_l072z_lrwan1/b_l072z_lrwan1.dts:32 */
			label = "Green LED 2";      /* in zephyr/boards/st/b_l072z_lrwan1/b_l072z_lrwan1.dts:33 */
		};

		/* node '/leds/led_2' defined in zephyr/boards/st/b_l072z_lrwan1/b_l072z_lrwan1.dts:36 */
		blue_led: led_2 {
			gpios = < &gpiob 0x6 0x0 >; /* in zephyr/boards/st/b_l072z_lrwan1/b_l072z_lrwan1.dts:37 */
			label = "Blue LED";         /* in zephyr/boards/st/b_l072z_lrwan1/b_l072z_lrwan1.dts:38 */
		};

		/* node '/leds/led_3' defined in zephyr/boards/st/b_l072z_lrwan1/b_l072z_lrwan1.dts:41 */
		red_led: led_3 {
			gpios = < &gpiob 0x7 0x0 >; /* in zephyr/boards/st/b_l072z_lrwan1/b_l072z_lrwan1.dts:42 */
			label = "Red LED";          /* in zephyr/boards/st/b_l072z_lrwan1/b_l072z_lrwan1.dts:43 */
		};
	};

	/* node '/gpio_keys' defined in zephyr/boards/st/b_l072z_lrwan1/b_l072z_lrwan1.dts:47 */
	gpio_keys {
		compatible = "gpio-keys"; /* in zephyr/boards/st/b_l072z_lrwan1/b_l072z_lrwan1.dts:48 */

		/* node '/gpio_keys/button_0' defined in zephyr/boards/st/b_l072z_lrwan1/b_l072z_lrwan1.dts:50 */
		user_button: button_0 {
			label = "Push button switch"; /* in zephyr/boards/st/b_l072z_lrwan1/b_l072z_lrwan1.dts:51 */
			gpios = < &gpiob 0x2 0x1 >;   /* in zephyr/boards/st/b_l072z_lrwan1/b_l072z_lrwan1.dts:52 */
			zephyr,code = < 0xb >;        /* in zephyr/boards/st/b_l072z_lrwan1/b_l072z_lrwan1.dts:53 */
		};
	};
};
